# MSS_CTRL_MSS_CTRL_50D00000h register map
Vendor: Texas Instruments
Registers are 32-bit, read-write, reset values left out (the file's numbers can be read two ways) unless marked. A register's access mark holds for its fields unless they carry their own. Offsets are as the file gives them; [hi:lo] are bit positions.

## MSS_CTRL (part 5 of 6)
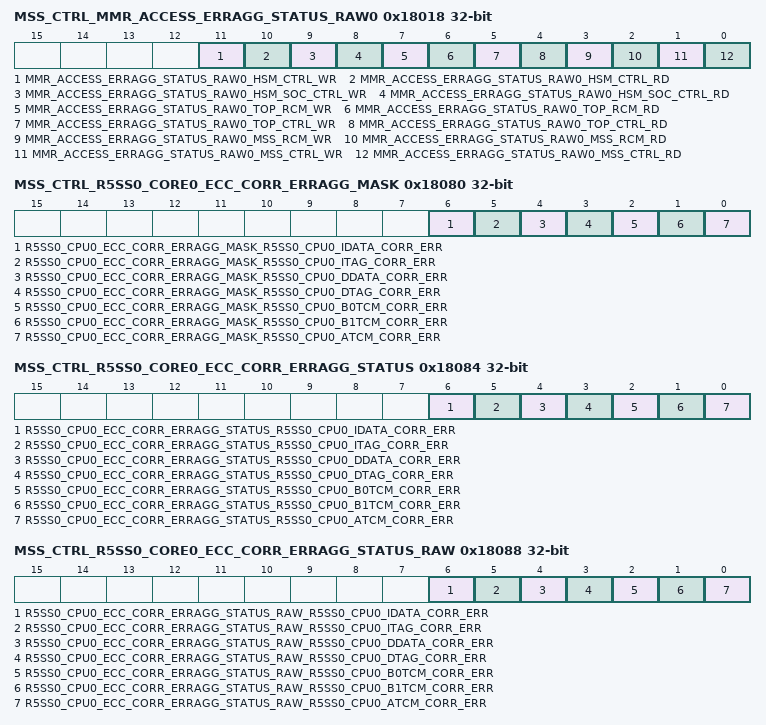
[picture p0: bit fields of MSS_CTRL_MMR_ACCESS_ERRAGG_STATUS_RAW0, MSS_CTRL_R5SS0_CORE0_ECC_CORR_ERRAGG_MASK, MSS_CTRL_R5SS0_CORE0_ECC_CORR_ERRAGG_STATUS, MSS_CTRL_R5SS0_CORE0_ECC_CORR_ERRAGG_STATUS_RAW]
0x18018 MSS_CTRL_MMR_ACCESS_ERRAGG_STATUS_RAW0
  [11] MMR_ACCESS_ERRAGG_STATUS_RAW0_HSM_CTRL_WR — Raw Status of Interrupt from HSM_CTRL. Set irrespective if the Interupt is masked or unmasked in MMR_ACCESS_ERRAGG_MASK0
  [10] MMR_ACCESS_ERRAGG_STATUS_RAW0_HSM_CTRL_RD — Raw Status of Interrupt from HSM_CTRL. Set irrespective if the Interupt is masked or unmasked in MMR_ACCESS_ERRAGG_MASK0
  [9] MMR_ACCESS_ERRAGG_STATUS_RAW0_HSM_SOC_CTRL_WR — Raw Status of Interrupt from HSM_SOC_CTRL. Set irrespective if the Interupt is masked or unmasked in MMR_ACCESS_ERRAGG_MASK0
  [8] MMR_ACCESS_ERRAGG_STATUS_RAW0_HSM_SOC_CTRL_RD — Raw Status of Interrupt from HSM_SOC_CTRL. Set irrespective if the Interupt is masked or unmasked in MMR_ACCESS_ERRAGG_MASK0
  [7] MMR_ACCESS_ERRAGG_STATUS_RAW0_TOP_RCM_WR — Raw Status of Interrupt from TOP_RCM. Set irrespective if the Interupt is masked or unmasked in MMR_ACCESS_ERRAGG_MASK0
  [6] MMR_ACCESS_ERRAGG_STATUS_RAW0_TOP_RCM_RD — Raw Status of Interrupt from TOP_RCM. Set irrespective if the Interupt is masked or unmasked in MMR_ACCESS_ERRAGG_MASK0
  [5] MMR_ACCESS_ERRAGG_STATUS_RAW0_TOP_CTRL_WR — Raw Status of Interrupt from TOP_CTRL. Set irrespective if the Interupt is masked or unmasked in MMR_ACCESS_ERRAGG_MASK0
  [4] MMR_ACCESS_ERRAGG_STATUS_RAW0_TOP_CTRL_RD — Raw Status of Interrupt from TOP_CTRL. Set irrespective if the Interupt is masked or unmasked in MMR_ACCESS_ERRAGG_MASK0
  [3] MMR_ACCESS_ERRAGG_STATUS_RAW0_MSS_RCM_WR — Raw Status of Interrupt from MSS_RCM. Set irrespective if the Interupt is masked or unmasked in MMR_ACCESS_ERRAGG_MASK0
  [2] MMR_ACCESS_ERRAGG_STATUS_RAW0_MSS_RCM_RD — Raw Status of Interrupt from MSS_RCM. Set irrespective if the Interupt is masked or unmasked in MMR_ACCESS_ERRAGG_MASK0
  [1] MMR_ACCESS_ERRAGG_STATUS_RAW0_MSS_CTRL_WR — Raw Status of Interrupt from MSS_CTRL. Set irrespective if the Interupt is masked or unmasked in MMR_ACCESS_ERRAGG_MASK0
  [0] MMR_ACCESS_ERRAGG_STATUS_RAW0_MSS_CTRL_RD — Raw Status of Interrupt from MSS_CTRL. Set irrespective if the Interupt is masked or unmasked in MMR_ACCESS_ERRAGG_MASK0
0x18080 MSS_CTRL_R5SS0_CORE0_ECC_CORR_ERRAGG_MASK
  [6] R5SS0_CPU0_ECC_CORR_ERRAGG_MASK_R5SS0_CPU0_IDATA_CORR_ERR — Mask Interrupt for correctable errors to aggregated Interrupt of corresponding CPU1'b1 : Interrupt is Masked1'b0 : Interrupt is Unmasked
  [5] R5SS0_CPU0_ECC_CORR_ERRAGG_MASK_R5SS0_CPU0_ITAG_CORR_ERR — Mask Interrupt for correctable errors to aggregated Interrupt of corresponding CPU1'b1 : Interrupt is Masked1'b0 : Interrupt is Unmasked
  [4] R5SS0_CPU0_ECC_CORR_ERRAGG_MASK_R5SS0_CPU0_DDATA_CORR_ERR — Mask Interrupt for correctable errors to aggregated Interrupt of corresponding CPU1'b1 : Interrupt is Masked1'b0 : Interrupt is Unmasked
  [3] R5SS0_CPU0_ECC_CORR_ERRAGG_MASK_R5SS0_CPU0_DTAG_CORR_ERR — Mask Interrupt for correctable errors to aggregated Interrupt of corresponding CPU1'b1 : Interrupt is Masked1'b0 : Interrupt is Unmasked
  [2] R5SS0_CPU0_ECC_CORR_ERRAGG_MASK_R5SS0_CPU0_B0TCM_CORR_ERR — Mask Interrupt for correctable errors to aggregated Interrupt of corresponding CPU1'b1 : Interrupt is Masked1'b0 : Interrupt is Unmasked
  [1] R5SS0_CPU0_ECC_CORR_ERRAGG_MASK_R5SS0_CPU0_B1TCM_CORR_ERR — Mask Interrupt for correctable errors to aggregated Interrupt of corresponding CPU1'b1 : Interrupt is Masked1'b0 : Interrupt is Unmasked
  [0] R5SS0_CPU0_ECC_CORR_ERRAGG_MASK_R5SS0_CPU0_ATCM_CORR_ERR — Mask Interrupt for correctable errors to aggregated Interrupt of corresponding CPU1'b1 : Interrupt is Masked1'b0 : Interrupt is Unmasked
0x18084 MSS_CTRL_R5SS0_CORE0_ECC_CORR_ERRAGG_STATUS
  [6] R5SS0_CPU0_ECC_CORR_ERRAGG_STATUS_R5SS0_CPU0_IDATA_CORR_ERR — Status of Interrupt from correctable error of corresponding CPUSet only if Interupt is unmasked in corresponding R5SS*_CPU*_ECC_CORR_ERRAGG_MASK registerWrie 0x1 to clear this interrupt.
  [5] R5SS0_CPU0_ECC_CORR_ERRAGG_STATUS_R5SS0_CPU0_ITAG_CORR_ERR — Status of Interrupt from correctable error of corresponding CPUSet only if Interupt is unmasked in corresponding R5SS*_CPU*_ECC_CORR_ERRAGG_MASK registerWrie 0x1 to clear this interrupt.
  [4] R5SS0_CPU0_ECC_CORR_ERRAGG_STATUS_R5SS0_CPU0_DDATA_CORR_ERR — Status of Interrupt from correctable error of corresponding CPUSet only if Interupt is unmasked in corresponding R5SS*_CPU*_ECC_CORR_ERRAGG_MASK registerWrie 0x1 to clear this interrupt.
  [3] R5SS0_CPU0_ECC_CORR_ERRAGG_STATUS_R5SS0_CPU0_DTAG_CORR_ERR — Status of Interrupt from correctable error of corresponding CPUSet only if Interupt is unmasked in corresponding R5SS*_CPU*_ECC_CORR_ERRAGG_MASK registerWrie 0x1 to clear this interrupt.
  [2] R5SS0_CPU0_ECC_CORR_ERRAGG_STATUS_R5SS0_CPU0_B0TCM_CORR_ERR — Status of Interrupt from correctable error of corresponding CPUSet only if Interupt is unmasked in corresponding R5SS*_CPU*_ECC_CORR_ERRAGG_MASK registerWrie 0x1 to clear this interrupt.
  [1] R5SS0_CPU0_ECC_CORR_ERRAGG_STATUS_R5SS0_CPU0_B1TCM_CORR_ERR — Status of Interrupt from correctable error of corresponding CPUSet only if Interupt is unmasked in corresponding R5SS*_CPU*_ECC_CORR_ERRAGG_MASK registerWrie 0x1 to clear this interrupt.
  [0] R5SS0_CPU0_ECC_CORR_ERRAGG_STATUS_R5SS0_CPU0_ATCM_CORR_ERR — Status of Interrupt from correctable error of corresponding CPUSet only if Interupt is unmasked in corresponding R5SS*_CPU*_ECC_CORR_ERRAGG_MASK registerWrie 0x1 to clear this interrupt.
0x18088 MSS_CTRL_R5SS0_CORE0_ECC_CORR_ERRAGG_STATUS_RAW
  [6] R5SS0_CPU0_ECC_CORR_ERRAGG_STATUS_RAW_R5SS0_CPU0_IDATA_CORR_ERR — Raw Status of Interrupt from correctable error of corresponding CPUSet only if Interupt is unmasked in corresponding R5SS*_CPU*_ECC_CORR_ERRAGG_MASK registerWrie 0x1 to clear this interrupt.
  [5] R5SS0_CPU0_ECC_CORR_ERRAGG_STATUS_RAW_R5SS0_CPU0_ITAG_CORR_ERR — Raw Status of Interrupt from correctable error of corresponding CPUSet only if Interupt is unmasked in corresponding R5SS*_CPU*_ECC_CORR_ERRAGG_MASK registerWrie 0x1 to clear this interrupt.
  [4] R5SS0_CPU0_ECC_CORR_ERRAGG_STATUS_RAW_R5SS0_CPU0_DDATA_CORR_ERR — Raw Status of Interrupt from correctable error of corresponding CPUSet only if Interupt is unmasked in corresponding R5SS*_CPU*_ECC_CORR_ERRAGG_MASK registerWrie 0x1 to clear this interrupt.
  [3] R5SS0_CPU0_ECC_CORR_ERRAGG_STATUS_RAW_R5SS0_CPU0_DTAG_CORR_ERR — Raw Status of Interrupt from correctable error of corresponding CPUSet only if Interupt is unmasked in corresponding R5SS*_CPU*_ECC_CORR_ERRAGG_MASK registerWrie 0x1 to clear this interrupt.
  [2] R5SS0_CPU0_ECC_CORR_ERRAGG_STATUS_RAW_R5SS0_CPU0_B0TCM_CORR_ERR — Raw Status of Interrupt from correctable error of corresponding CPUSet only if Interupt is unmasked in corresponding R5SS*_CPU*_ECC_CORR_ERRAGG_MASK registerWrie 0x1 to clear this interrupt.
  [1] R5SS0_CPU0_ECC_CORR_ERRAGG_STATUS_RAW_R5SS0_CPU0_B1TCM_CORR_ERR — Raw Status of Interrupt from correctable error of corresponding CPUSet only if Interupt is unmasked in corresponding R5SS*_CPU*_ECC_CORR_ERRAGG_MASK registerWrie 0x1 to clear this interrupt.
  [0] R5SS0_CPU0_ECC_CORR_ERRAGG_STATUS_RAW_R5SS0_CPU0_ATCM_CORR_ERR — Raw Status of Interrupt from correctable error of corresponding CPUSet only if Interupt is unmasked in corresponding R5SS*_CPU*_ECC_CORR_ERRAGG_MASK registerWrie 0x1 to clear this interrupt.
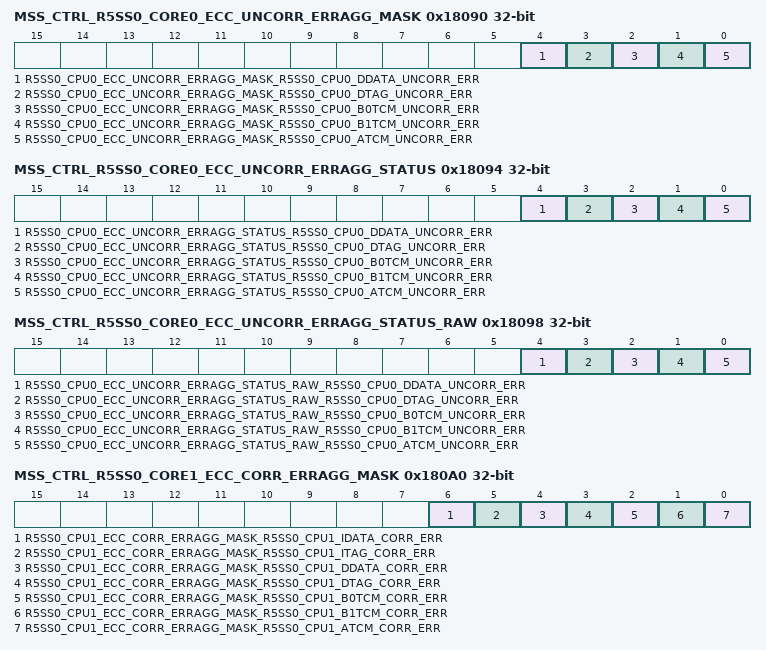
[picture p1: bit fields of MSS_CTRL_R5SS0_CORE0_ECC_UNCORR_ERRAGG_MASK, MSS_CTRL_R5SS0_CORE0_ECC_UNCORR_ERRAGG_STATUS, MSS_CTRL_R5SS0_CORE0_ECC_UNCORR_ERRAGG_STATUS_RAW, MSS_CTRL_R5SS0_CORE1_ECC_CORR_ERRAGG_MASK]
0x18090 MSS_CTRL_R5SS0_CORE0_ECC_UNCORR_ERRAGG_MASK
  [4] R5SS0_CPU0_ECC_UNCORR_ERRAGG_MASK_R5SS0_CPU0_DDATA_UNCORR_ERR — Mask Interrupt for correctable errors to aggregated Interrupt of corresponding CPU1'b1 : Interrupt is Masked1'b0 : Interrupt is Unmasked
  [3] R5SS0_CPU0_ECC_UNCORR_ERRAGG_MASK_R5SS0_CPU0_DTAG_UNCORR_ERR — Mask Interrupt for correctable errors to aggregated Interrupt of corresponding CPU1'b1 : Interrupt is Masked1'b0 : Interrupt is Unmasked
  [2] R5SS0_CPU0_ECC_UNCORR_ERRAGG_MASK_R5SS0_CPU0_B0TCM_UNCORR_ERR — Mask Interrupt for correctable errors to aggregated Interrupt of corresponding CPU1'b1 : Interrupt is Masked1'b0 : Interrupt is Unmasked
  [1] R5SS0_CPU0_ECC_UNCORR_ERRAGG_MASK_R5SS0_CPU0_B1TCM_UNCORR_ERR — Mask Interrupt for correctable errors to aggregated Interrupt of corresponding CPU1'b1 : Interrupt is Masked1'b0 : Interrupt is Unmasked
  [0] R5SS0_CPU0_ECC_UNCORR_ERRAGG_MASK_R5SS0_CPU0_ATCM_UNCORR_ERR — Mask Interrupt for correctable errors to aggregated Interrupt of corresponding CPU1'b1 : Interrupt is Masked1'b0 : Interrupt is Unmasked
0x18094 MSS_CTRL_R5SS0_CORE0_ECC_UNCORR_ERRAGG_STATUS
  [4] R5SS0_CPU0_ECC_UNCORR_ERRAGG_STATUS_R5SS0_CPU0_DDATA_UNCORR_ERR — Status of Interrupt from correctable error of corresponding CPUSet only if Interupt is unmasked in corresponding R5SS*_CPU*_ECC_UNCORR_ERRAGG_MASK registerWrie 0x1 to clear this interrupt.
  [3] R5SS0_CPU0_ECC_UNCORR_ERRAGG_STATUS_R5SS0_CPU0_DTAG_UNCORR_ERR — Status of Interrupt from correctable error of corresponding CPUSet only if Interupt is unmasked in corresponding R5SS*_CPU*_ECC_UNCORR_ERRAGG_MASK registerWrie 0x1 to clear this interrupt.
  [2] R5SS0_CPU0_ECC_UNCORR_ERRAGG_STATUS_R5SS0_CPU0_B0TCM_UNCORR_ERR — Status of Interrupt from correctable error of corresponding CPUSet only if Interupt is unmasked in corresponding R5SS*_CPU*_ECC_UNCORR_ERRAGG_MASK registerWrie 0x1 to clear this interrupt.
  [1] R5SS0_CPU0_ECC_UNCORR_ERRAGG_STATUS_R5SS0_CPU0_B1TCM_UNCORR_ERR — Status of Interrupt from correctable error of corresponding CPUSet only if Interupt is unmasked in corresponding R5SS*_CPU*_ECC_UNCORR_ERRAGG_MASK registerWrie 0x1 to clear this interrupt.
  [0] R5SS0_CPU0_ECC_UNCORR_ERRAGG_STATUS_R5SS0_CPU0_ATCM_UNCORR_ERR — Status of Interrupt from correctable error of corresponding CPUSet only if Interupt is unmasked in corresponding R5SS*_CPU*_ECC_UNCORR_ERRAGG_MASK registerWrie 0x1 to clear this interrupt.
0x18098 MSS_CTRL_R5SS0_CORE0_ECC_UNCORR_ERRAGG_STATUS_RAW
  [4] R5SS0_CPU0_ECC_UNCORR_ERRAGG_STATUS_RAW_R5SS0_CPU0_DDATA_UNCORR_ERR — Raw Status of Interrupt from correctable error of corresponding CPUSet only if Interupt is unmasked in corresponding R5SS*_CPU*_ECC_UNCORR_ERRAGG_MASK registerWrie 0x1 to clear this interrupt.
  [3] R5SS0_CPU0_ECC_UNCORR_ERRAGG_STATUS_RAW_R5SS0_CPU0_DTAG_UNCORR_ERR — Raw Status of Interrupt from correctable error of corresponding CPUSet only if Interupt is unmasked in corresponding R5SS*_CPU*_ECC_UNCORR_ERRAGG_MASK registerWrie 0x1 to clear this interrupt.
  [2] R5SS0_CPU0_ECC_UNCORR_ERRAGG_STATUS_RAW_R5SS0_CPU0_B0TCM_UNCORR_ERR — Raw Status of Interrupt from correctable error of corresponding CPUSet only if Interupt is unmasked in corresponding R5SS*_CPU*_ECC_UNCORR_ERRAGG_MASK registerWrie 0x1 to clear this interrupt.
  [1] R5SS0_CPU0_ECC_UNCORR_ERRAGG_STATUS_RAW_R5SS0_CPU0_B1TCM_UNCORR_ERR — Raw Status of Interrupt from correctable error of corresponding CPUSet only if Interupt is unmasked in corresponding R5SS*_CPU*_ECC_UNCORR_ERRAGG_MASK registerWrie 0x1 to clear this interrupt.
  [0] R5SS0_CPU0_ECC_UNCORR_ERRAGG_STATUS_RAW_R5SS0_CPU0_ATCM_UNCORR_ERR — Raw Status of Interrupt from correctable error of corresponding CPUSet only if Interupt is unmasked in corresponding R5SS*_CPU*_ECC_UNCORR_ERRAGG_MASK registerWrie 0x1 to clear this interrupt.
0x180A0 MSS_CTRL_R5SS0_CORE1_ECC_CORR_ERRAGG_MASK
  [6] R5SS0_CPU1_ECC_CORR_ERRAGG_MASK_R5SS0_CPU1_IDATA_CORR_ERR — Mask Interrupt for correctable errors to aggregated Interrupt of corresponding CPU1'b1 : Interrupt is Masked1'b0 : Interrupt is Unmasked
  [5] R5SS0_CPU1_ECC_CORR_ERRAGG_MASK_R5SS0_CPU1_ITAG_CORR_ERR — Mask Interrupt for correctable errors to aggregated Interrupt of corresponding CPU1'b1 : Interrupt is Masked1'b0 : Interrupt is Unmasked
  [4] R5SS0_CPU1_ECC_CORR_ERRAGG_MASK_R5SS0_CPU1_DDATA_CORR_ERR — Mask Interrupt for correctable errors to aggregated Interrupt of corresponding CPU1'b1 : Interrupt is Masked1'b0 : Interrupt is Unmasked
  [3] R5SS0_CPU1_ECC_CORR_ERRAGG_MASK_R5SS0_CPU1_DTAG_CORR_ERR — Mask Interrupt for correctable errors to aggregated Interrupt of corresponding CPU1'b1 : Interrupt is Masked1'b0 : Interrupt is Unmasked
  [2] R5SS0_CPU1_ECC_CORR_ERRAGG_MASK_R5SS0_CPU1_B0TCM_CORR_ERR — Mask Interrupt for correctable errors to aggregated Interrupt of corresponding CPU1'b1 : Interrupt is Masked1'b0 : Interrupt is Unmasked
  [1] R5SS0_CPU1_ECC_CORR_ERRAGG_MASK_R5SS0_CPU1_B1TCM_CORR_ERR — Mask Interrupt for correctable errors to aggregated Interrupt of corresponding CPU1'b1 : Interrupt is Masked1'b0 : Interrupt is Unmasked
  [0] R5SS0_CPU1_ECC_CORR_ERRAGG_MASK_R5SS0_CPU1_ATCM_CORR_ERR — Mask Interrupt for correctable errors to aggregated Interrupt of corresponding CPU1'b1 : Interrupt is Masked1'b0 : Interrupt is Unmasked
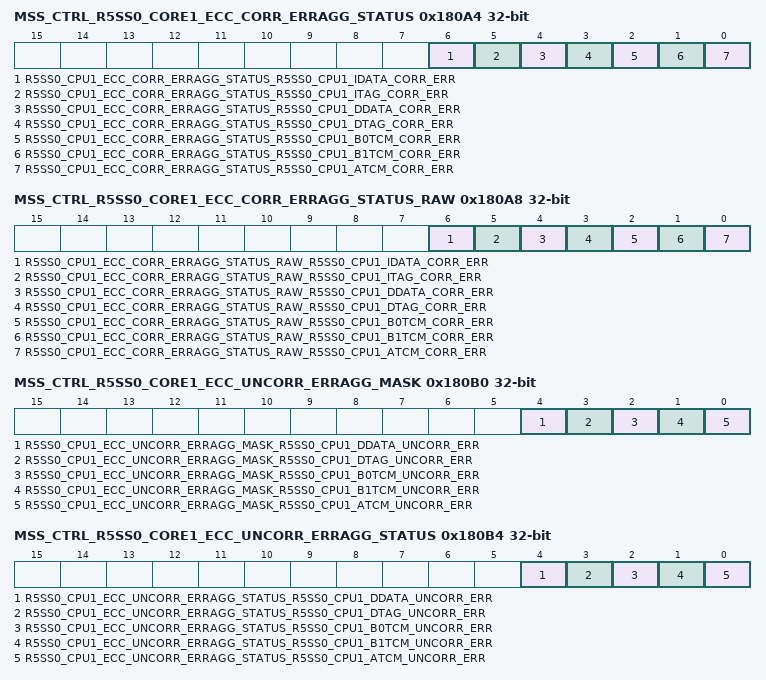
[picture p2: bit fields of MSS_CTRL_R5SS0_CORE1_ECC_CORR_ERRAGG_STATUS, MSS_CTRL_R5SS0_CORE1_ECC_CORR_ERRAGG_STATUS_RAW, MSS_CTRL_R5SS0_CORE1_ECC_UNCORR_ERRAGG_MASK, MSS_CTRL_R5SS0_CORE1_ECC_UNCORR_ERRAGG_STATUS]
0x180A4 MSS_CTRL_R5SS0_CORE1_ECC_CORR_ERRAGG_STATUS
  [6] R5SS0_CPU1_ECC_CORR_ERRAGG_STATUS_R5SS0_CPU1_IDATA_CORR_ERR — Status of Interrupt from correctable error of corresponding CPUSet only if Interupt is unmasked in corresponding R5SS*_CPU*_ECC_CORR_ERRAGG_MASK registerWrie 0x1 to clear this interrupt.
  [5] R5SS0_CPU1_ECC_CORR_ERRAGG_STATUS_R5SS0_CPU1_ITAG_CORR_ERR — Status of Interrupt from correctable error of corresponding CPUSet only if Interupt is unmasked in corresponding R5SS*_CPU*_ECC_CORR_ERRAGG_MASK registerWrie 0x1 to clear this interrupt.
  [4] R5SS0_CPU1_ECC_CORR_ERRAGG_STATUS_R5SS0_CPU1_DDATA_CORR_ERR — Status of Interrupt from correctable error of corresponding CPUSet only if Interupt is unmasked in corresponding R5SS*_CPU*_ECC_CORR_ERRAGG_MASK registerWrie 0x1 to clear this interrupt.
  [3] R5SS0_CPU1_ECC_CORR_ERRAGG_STATUS_R5SS0_CPU1_DTAG_CORR_ERR — Status of Interrupt from correctable error of corresponding CPUSet only if Interupt is unmasked in corresponding R5SS*_CPU*_ECC_CORR_ERRAGG_MASK registerWrie 0x1 to clear this interrupt.
  [2] R5SS0_CPU1_ECC_CORR_ERRAGG_STATUS_R5SS0_CPU1_B0TCM_CORR_ERR — Status of Interrupt from correctable error of corresponding CPUSet only if Interupt is unmasked in corresponding R5SS*_CPU*_ECC_CORR_ERRAGG_MASK registerWrie 0x1 to clear this interrupt.
  [1] R5SS0_CPU1_ECC_CORR_ERRAGG_STATUS_R5SS0_CPU1_B1TCM_CORR_ERR — Status of Interrupt from correctable error of corresponding CPUSet only if Interupt is unmasked in corresponding R5SS*_CPU*_ECC_CORR_ERRAGG_MASK registerWrie 0x1 to clear this interrupt.
  [0] R5SS0_CPU1_ECC_CORR_ERRAGG_STATUS_R5SS0_CPU1_ATCM_CORR_ERR — Status of Interrupt from correctable error of corresponding CPUSet only if Interupt is unmasked in corresponding R5SS*_CPU*_ECC_CORR_ERRAGG_MASK registerWrie 0x1 to clear this interrupt.
0x180A8 MSS_CTRL_R5SS0_CORE1_ECC_CORR_ERRAGG_STATUS_RAW
  [6] R5SS0_CPU1_ECC_CORR_ERRAGG_STATUS_RAW_R5SS0_CPU1_IDATA_CORR_ERR — Raw Status of Interrupt from correctable error of corresponding CPUSet only if Interupt is unmasked in corresponding R5SS*_CPU*_ECC_CORR_ERRAGG_MASK registerWrie 0x1 to clear this interrupt.
  [5] R5SS0_CPU1_ECC_CORR_ERRAGG_STATUS_RAW_R5SS0_CPU1_ITAG_CORR_ERR — Raw Status of Interrupt from correctable error of corresponding CPUSet only if Interupt is unmasked in corresponding R5SS*_CPU*_ECC_CORR_ERRAGG_MASK registerWrie 0x1 to clear this interrupt.
  [4] R5SS0_CPU1_ECC_CORR_ERRAGG_STATUS_RAW_R5SS0_CPU1_DDATA_CORR_ERR — Raw Status of Interrupt from correctable error of corresponding CPUSet only if Interupt is unmasked in corresponding R5SS*_CPU*_ECC_CORR_ERRAGG_MASK registerWrie 0x1 to clear this interrupt.
  [3] R5SS0_CPU1_ECC_CORR_ERRAGG_STATUS_RAW_R5SS0_CPU1_DTAG_CORR_ERR — Raw Status of Interrupt from correctable error of corresponding CPUSet only if Interupt is unmasked in corresponding R5SS*_CPU*_ECC_CORR_ERRAGG_MASK registerWrie 0x1 to clear this interrupt.
  [2] R5SS0_CPU1_ECC_CORR_ERRAGG_STATUS_RAW_R5SS0_CPU1_B0TCM_CORR_ERR — Raw Status of Interrupt from correctable error of corresponding CPUSet only if Interupt is unmasked in corresponding R5SS*_CPU*_ECC_CORR_ERRAGG_MASK registerWrie 0x1 to clear this interrupt.
  [1] R5SS0_CPU1_ECC_CORR_ERRAGG_STATUS_RAW_R5SS0_CPU1_B1TCM_CORR_ERR — Raw Status of Interrupt from correctable error of corresponding CPUSet only if Interupt is unmasked in corresponding R5SS*_CPU*_ECC_CORR_ERRAGG_MASK registerWrie 0x1 to clear this interrupt.
  [0] R5SS0_CPU1_ECC_CORR_ERRAGG_STATUS_RAW_R5SS0_CPU1_ATCM_CORR_ERR — Raw Status of Interrupt from correctable error of corresponding CPUSet only if Interupt is unmasked in corresponding R5SS*_CPU*_ECC_CORR_ERRAGG_MASK registerWrie 0x1 to clear this interrupt.
0x180B0 MSS_CTRL_R5SS0_CORE1_ECC_UNCORR_ERRAGG_MASK
  [4] R5SS0_CPU1_ECC_UNCORR_ERRAGG_MASK_R5SS0_CPU1_DDATA_UNCORR_ERR — Mask Interrupt for correctable errors to aggregated Interrupt of corresponding CPU1'b1 : Interrupt is Masked1'b0 : Interrupt is Unmasked
  [3] R5SS0_CPU1_ECC_UNCORR_ERRAGG_MASK_R5SS0_CPU1_DTAG_UNCORR_ERR — Mask Interrupt for correctable errors to aggregated Interrupt of corresponding CPU1'b1 : Interrupt is Masked1'b0 : Interrupt is Unmasked
  [2] R5SS0_CPU1_ECC_UNCORR_ERRAGG_MASK_R5SS0_CPU1_B0TCM_UNCORR_ERR — Mask Interrupt for correctable errors to aggregated Interrupt of corresponding CPU1'b1 : Interrupt is Masked1'b0 : Interrupt is Unmasked
  [1] R5SS0_CPU1_ECC_UNCORR_ERRAGG_MASK_R5SS0_CPU1_B1TCM_UNCORR_ERR — Mask Interrupt for correctable errors to aggregated Interrupt of corresponding CPU1'b1 : Interrupt is Masked1'b0 : Interrupt is Unmasked
  [0] R5SS0_CPU1_ECC_UNCORR_ERRAGG_MASK_R5SS0_CPU1_ATCM_UNCORR_ERR — Mask Interrupt for correctable errors to aggregated Interrupt of corresponding CPU1'b1 : Interrupt is Masked1'b0 : Interrupt is Unmasked
0x180B4 MSS_CTRL_R5SS0_CORE1_ECC_UNCORR_ERRAGG_STATUS
  [4] R5SS0_CPU1_ECC_UNCORR_ERRAGG_STATUS_R5SS0_CPU1_DDATA_UNCORR_ERR — Status of Interrupt from correctable error of corresponding CPUSet only if Interupt is unmasked in corresponding R5SS*_CPU*_ECC_UNCORR_ERRAGG_MASK registerWrie 0x1 to clear this interrupt.
  [3] R5SS0_CPU1_ECC_UNCORR_ERRAGG_STATUS_R5SS0_CPU1_DTAG_UNCORR_ERR — Status of Interrupt from correctable error of corresponding CPUSet only if Interupt is unmasked in corresponding R5SS*_CPU*_ECC_UNCORR_ERRAGG_MASK registerWrie 0x1 to clear this interrupt.
  [2] R5SS0_CPU1_ECC_UNCORR_ERRAGG_STATUS_R5SS0_CPU1_B0TCM_UNCORR_ERR — Status of Interrupt from correctable error of corresponding CPUSet only if Interupt is unmasked in corresponding R5SS*_CPU*_ECC_UNCORR_ERRAGG_MASK registerWrie 0x1 to clear this interrupt.
  [1] R5SS0_CPU1_ECC_UNCORR_ERRAGG_STATUS_R5SS0_CPU1_B1TCM_UNCORR_ERR — Status of Interrupt from correctable error of corresponding CPUSet only if Interupt is unmasked in corresponding R5SS*_CPU*_ECC_UNCORR_ERRAGG_MASK registerWrie 0x1 to clear this interrupt.
  [0] R5SS0_CPU1_ECC_UNCORR_ERRAGG_STATUS_R5SS0_CPU1_ATCM_UNCORR_ERR — Status of Interrupt from correctable error of corresponding CPUSet only if Interupt is unmasked in corresponding R5SS*_CPU*_ECC_UNCORR_ERRAGG_MASK registerWrie 0x1 to clear this interrupt.
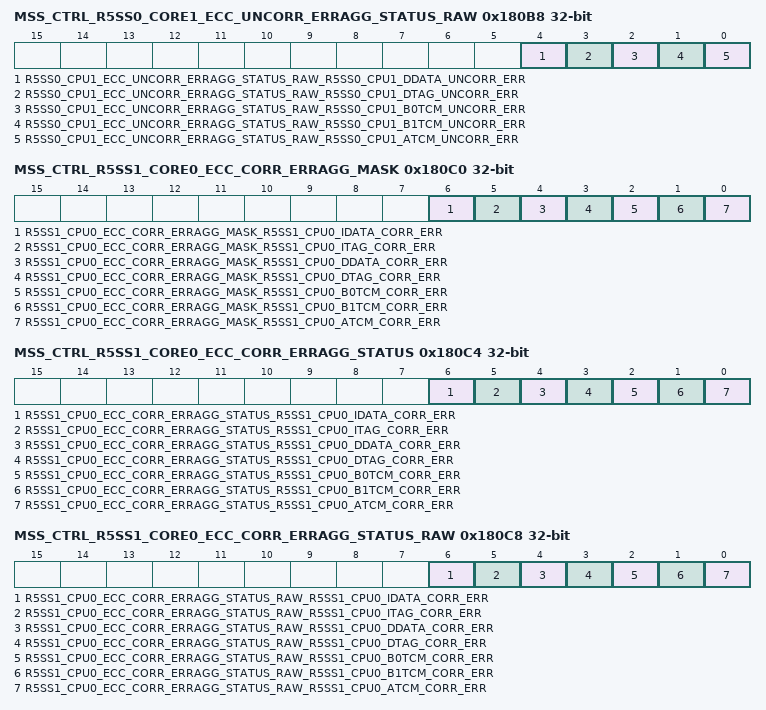
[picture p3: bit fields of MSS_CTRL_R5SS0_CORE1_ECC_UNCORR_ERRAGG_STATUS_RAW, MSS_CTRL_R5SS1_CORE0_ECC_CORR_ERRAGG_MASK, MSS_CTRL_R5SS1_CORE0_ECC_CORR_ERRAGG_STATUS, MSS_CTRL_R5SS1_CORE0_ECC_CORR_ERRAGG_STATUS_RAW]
0x180B8 MSS_CTRL_R5SS0_CORE1_ECC_UNCORR_ERRAGG_STATUS_RAW
  [4] R5SS0_CPU1_ECC_UNCORR_ERRAGG_STATUS_RAW_R5SS0_CPU1_DDATA_UNCORR_ERR — Raw Status of Interrupt from correctable error of corresponding CPUSet only if Interupt is unmasked in corresponding R5SS*_CPU*_ECC_UNCORR_ERRAGG_MASK registerWrie 0x1 to clear this interrupt.
  [3] R5SS0_CPU1_ECC_UNCORR_ERRAGG_STATUS_RAW_R5SS0_CPU1_DTAG_UNCORR_ERR — Raw Status of Interrupt from correctable error of corresponding CPUSet only if Interupt is unmasked in corresponding R5SS*_CPU*_ECC_UNCORR_ERRAGG_MASK registerWrie 0x1 to clear this interrupt.
  [2] R5SS0_CPU1_ECC_UNCORR_ERRAGG_STATUS_RAW_R5SS0_CPU1_B0TCM_UNCORR_ERR — Raw Status of Interrupt from correctable error of corresponding CPUSet only if Interupt is unmasked in corresponding R5SS*_CPU*_ECC_UNCORR_ERRAGG_MASK registerWrie 0x1 to clear this interrupt.
  [1] R5SS0_CPU1_ECC_UNCORR_ERRAGG_STATUS_RAW_R5SS0_CPU1_B1TCM_UNCORR_ERR — Raw Status of Interrupt from correctable error of corresponding CPUSet only if Interupt is unmasked in corresponding R5SS*_CPU*_ECC_UNCORR_ERRAGG_MASK registerWrie 0x1 to clear this interrupt.
  [0] R5SS0_CPU1_ECC_UNCORR_ERRAGG_STATUS_RAW_R5SS0_CPU1_ATCM_UNCORR_ERR — Raw Status of Interrupt from correctable error of corresponding CPUSet only if Interupt is unmasked in corresponding R5SS*_CPU*_ECC_UNCORR_ERRAGG_MASK registerWrie 0x1 to clear this interrupt.
0x180C0 MSS_CTRL_R5SS1_CORE0_ECC_CORR_ERRAGG_MASK
  [6] R5SS1_CPU0_ECC_CORR_ERRAGG_MASK_R5SS1_CPU0_IDATA_CORR_ERR — Mask Interrupt for correctable errors to aggregated Interrupt of corresponding CPU1'b1 : Interrupt is Masked1'b0 : Interrupt is Unmasked
  [5] R5SS1_CPU0_ECC_CORR_ERRAGG_MASK_R5SS1_CPU0_ITAG_CORR_ERR — Mask Interrupt for correctable errors to aggregated Interrupt of corresponding CPU1'b1 : Interrupt is Masked1'b0 : Interrupt is Unmasked
  [4] R5SS1_CPU0_ECC_CORR_ERRAGG_MASK_R5SS1_CPU0_DDATA_CORR_ERR — Mask Interrupt for correctable errors to aggregated Interrupt of corresponding CPU1'b1 : Interrupt is Masked1'b0 : Interrupt is Unmasked
  [3] R5SS1_CPU0_ECC_CORR_ERRAGG_MASK_R5SS1_CPU0_DTAG_CORR_ERR — Mask Interrupt for correctable errors to aggregated Interrupt of corresponding CPU1'b1 : Interrupt is Masked1'b0 : Interrupt is Unmasked
  [2] R5SS1_CPU0_ECC_CORR_ERRAGG_MASK_R5SS1_CPU0_B0TCM_CORR_ERR — Mask Interrupt for correctable errors to aggregated Interrupt of corresponding CPU1'b1 : Interrupt is Masked1'b0 : Interrupt is Unmasked
  [1] R5SS1_CPU0_ECC_CORR_ERRAGG_MASK_R5SS1_CPU0_B1TCM_CORR_ERR — Mask Interrupt for correctable errors to aggregated Interrupt of corresponding CPU1'b1 : Interrupt is Masked1'b0 : Interrupt is Unmasked
  [0] R5SS1_CPU0_ECC_CORR_ERRAGG_MASK_R5SS1_CPU0_ATCM_CORR_ERR — Mask Interrupt for correctable errors to aggregated Interrupt of corresponding CPU1'b1 : Interrupt is Masked1'b0 : Interrupt is Unmasked
0x180C4 MSS_CTRL_R5SS1_CORE0_ECC_CORR_ERRAGG_STATUS
  [6] R5SS1_CPU0_ECC_CORR_ERRAGG_STATUS_R5SS1_CPU0_IDATA_CORR_ERR — Status of Interrupt from correctable error of corresponding CPUSet only if Interupt is unmasked in corresponding R5SS*_CPU*_ECC_CORR_ERRAGG_MASK registerWrie 0x1 to clear this interrupt.
  [5] R5SS1_CPU0_ECC_CORR_ERRAGG_STATUS_R5SS1_CPU0_ITAG_CORR_ERR — Status of Interrupt from correctable error of corresponding CPUSet only if Interupt is unmasked in corresponding R5SS*_CPU*_ECC_CORR_ERRAGG_MASK registerWrie 0x1 to clear this interrupt.
  [4] R5SS1_CPU0_ECC_CORR_ERRAGG_STATUS_R5SS1_CPU0_DDATA_CORR_ERR — Status of Interrupt from correctable error of corresponding CPUSet only if Interupt is unmasked in corresponding R5SS*_CPU*_ECC_CORR_ERRAGG_MASK registerWrie 0x1 to clear this interrupt.
  [3] R5SS1_CPU0_ECC_CORR_ERRAGG_STATUS_R5SS1_CPU0_DTAG_CORR_ERR — Status of Interrupt from correctable error of corresponding CPUSet only if Interupt is unmasked in corresponding R5SS*_CPU*_ECC_CORR_ERRAGG_MASK registerWrie 0x1 to clear this interrupt.
  [2] R5SS1_CPU0_ECC_CORR_ERRAGG_STATUS_R5SS1_CPU0_B0TCM_CORR_ERR — Status of Interrupt from correctable error of corresponding CPUSet only if Interupt is unmasked in corresponding R5SS*_CPU*_ECC_CORR_ERRAGG_MASK registerWrie 0x1 to clear this interrupt.
  [1] R5SS1_CPU0_ECC_CORR_ERRAGG_STATUS_R5SS1_CPU0_B1TCM_CORR_ERR — Status of Interrupt from correctable error of corresponding CPUSet only if Interupt is unmasked in corresponding R5SS*_CPU*_ECC_CORR_ERRAGG_MASK registerWrie 0x1 to clear this interrupt.
  [0] R5SS1_CPU0_ECC_CORR_ERRAGG_STATUS_R5SS1_CPU0_ATCM_CORR_ERR — Status of Interrupt from correctable error of corresponding CPUSet only if Interupt is unmasked in corresponding R5SS*_CPU*_ECC_CORR_ERRAGG_MASK registerWrie 0x1 to clear this interrupt.
0x180C8 MSS_CTRL_R5SS1_CORE0_ECC_CORR_ERRAGG_STATUS_RAW
  [6] R5SS1_CPU0_ECC_CORR_ERRAGG_STATUS_RAW_R5SS1_CPU0_IDATA_CORR_ERR — Raw Status of Interrupt from correctable error of corresponding CPUSet only if Interupt is unmasked in corresponding R5SS*_CPU*_ECC_CORR_ERRAGG_MASK registerWrie 0x1 to clear this interrupt.
  [5] R5SS1_CPU0_ECC_CORR_ERRAGG_STATUS_RAW_R5SS1_CPU0_ITAG_CORR_ERR — Raw Status of Interrupt from correctable error of corresponding CPUSet only if Interupt is unmasked in corresponding R5SS*_CPU*_ECC_CORR_ERRAGG_MASK registerWrie 0x1 to clear this interrupt.
  [4] R5SS1_CPU0_ECC_CORR_ERRAGG_STATUS_RAW_R5SS1_CPU0_DDATA_CORR_ERR — Raw Status of Interrupt from correctable error of corresponding CPUSet only if Interupt is unmasked in corresponding R5SS*_CPU*_ECC_CORR_ERRAGG_MASK registerWrie 0x1 to clear this interrupt.
  [3] R5SS1_CPU0_ECC_CORR_ERRAGG_STATUS_RAW_R5SS1_CPU0_DTAG_CORR_ERR — Raw Status of Interrupt from correctable error of corresponding CPUSet only if Interupt is unmasked in corresponding R5SS*_CPU*_ECC_CORR_ERRAGG_MASK registerWrie 0x1 to clear this interrupt.
  [2] R5SS1_CPU0_ECC_CORR_ERRAGG_STATUS_RAW_R5SS1_CPU0_B0TCM_CORR_ERR — Raw Status of Interrupt from correctable error of corresponding CPUSet only if Interupt is unmasked in corresponding R5SS*_CPU*_ECC_CORR_ERRAGG_MASK registerWrie 0x1 to clear this interrupt.
  [1] R5SS1_CPU0_ECC_CORR_ERRAGG_STATUS_RAW_R5SS1_CPU0_B1TCM_CORR_ERR — Raw Status of Interrupt from correctable error of corresponding CPUSet only if Interupt is unmasked in corresponding R5SS*_CPU*_ECC_CORR_ERRAGG_MASK registerWrie 0x1 to clear this interrupt.
  [0] R5SS1_CPU0_ECC_CORR_ERRAGG_STATUS_RAW_R5SS1_CPU0_ATCM_CORR_ERR — Raw Status of Interrupt from correctable error of corresponding CPUSet only if Interupt is unmasked in corresponding R5SS*_CPU*_ECC_CORR_ERRAGG_MASK registerWrie 0x1 to clear this interrupt.
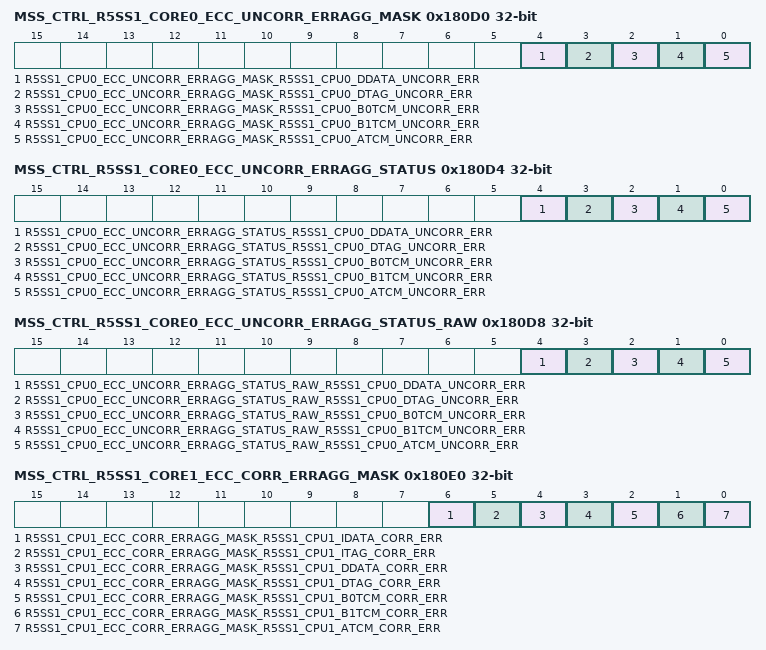
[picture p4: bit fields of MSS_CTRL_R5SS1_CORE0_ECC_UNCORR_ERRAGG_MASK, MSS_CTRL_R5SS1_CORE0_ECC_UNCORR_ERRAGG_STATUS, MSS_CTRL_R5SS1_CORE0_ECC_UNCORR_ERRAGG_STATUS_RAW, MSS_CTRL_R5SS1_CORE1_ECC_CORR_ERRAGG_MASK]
0x180D0 MSS_CTRL_R5SS1_CORE0_ECC_UNCORR_ERRAGG_MASK
  [4] R5SS1_CPU0_ECC_UNCORR_ERRAGG_MASK_R5SS1_CPU0_DDATA_UNCORR_ERR — Mask Interrupt for correctable errors to aggregated Interrupt of corresponding CPU1'b1 : Interrupt is Masked1'b0 : Interrupt is Unmasked
  [3] R5SS1_CPU0_ECC_UNCORR_ERRAGG_MASK_R5SS1_CPU0_DTAG_UNCORR_ERR — Mask Interrupt for correctable errors to aggregated Interrupt of corresponding CPU1'b1 : Interrupt is Masked1'b0 : Interrupt is Unmasked
  [2] R5SS1_CPU0_ECC_UNCORR_ERRAGG_MASK_R5SS1_CPU0_B0TCM_UNCORR_ERR — Mask Interrupt for correctable errors to aggregated Interrupt of corresponding CPU1'b1 : Interrupt is Masked1'b0 : Interrupt is Unmasked
  [1] R5SS1_CPU0_ECC_UNCORR_ERRAGG_MASK_R5SS1_CPU0_B1TCM_UNCORR_ERR — Mask Interrupt for correctable errors to aggregated Interrupt of corresponding CPU1'b1 : Interrupt is Masked1'b0 : Interrupt is Unmasked
  [0] R5SS1_CPU0_ECC_UNCORR_ERRAGG_MASK_R5SS1_CPU0_ATCM_UNCORR_ERR — Mask Interrupt for correctable errors to aggregated Interrupt of corresponding CPU1'b1 : Interrupt is Masked1'b0 : Interrupt is Unmasked
0x180D4 MSS_CTRL_R5SS1_CORE0_ECC_UNCORR_ERRAGG_STATUS
  [4] R5SS1_CPU0_ECC_UNCORR_ERRAGG_STATUS_R5SS1_CPU0_DDATA_UNCORR_ERR — Status of Interrupt from correctable error of corresponding CPUSet only if Interupt is unmasked in corresponding R5SS*_CPU*_ECC_UNCORR_ERRAGG_MASK registerWrie 0x1 to clear this interrupt.
  [3] R5SS1_CPU0_ECC_UNCORR_ERRAGG_STATUS_R5SS1_CPU0_DTAG_UNCORR_ERR — Status of Interrupt from correctable error of corresponding CPUSet only if Interupt is unmasked in corresponding R5SS*_CPU*_ECC_UNCORR_ERRAGG_MASK registerWrie 0x1 to clear this interrupt.
  [2] R5SS1_CPU0_ECC_UNCORR_ERRAGG_STATUS_R5SS1_CPU0_B0TCM_UNCORR_ERR — Status of Interrupt from correctable error of corresponding CPUSet only if Interupt is unmasked in corresponding R5SS*_CPU*_ECC_UNCORR_ERRAGG_MASK registerWrie 0x1 to clear this interrupt.
  [1] R5SS1_CPU0_ECC_UNCORR_ERRAGG_STATUS_R5SS1_CPU0_B1TCM_UNCORR_ERR — Status of Interrupt from correctable error of corresponding CPUSet only if Interupt is unmasked in corresponding R5SS*_CPU*_ECC_UNCORR_ERRAGG_MASK registerWrie 0x1 to clear this interrupt.
  [0] R5SS1_CPU0_ECC_UNCORR_ERRAGG_STATUS_R5SS1_CPU0_ATCM_UNCORR_ERR — Status of Interrupt from correctable error of corresponding CPUSet only if Interupt is unmasked in corresponding R5SS*_CPU*_ECC_UNCORR_ERRAGG_MASK registerWrie 0x1 to clear this interrupt.
0x180D8 MSS_CTRL_R5SS1_CORE0_ECC_UNCORR_ERRAGG_STATUS_RAW
  [4] R5SS1_CPU0_ECC_UNCORR_ERRAGG_STATUS_RAW_R5SS1_CPU0_DDATA_UNCORR_ERR — Raw Status of Interrupt from correctable error of corresponding CPUSet only if Interupt is unmasked in corresponding R5SS*_CPU*_ECC_UNCORR_ERRAGG_MASK registerWrie 0x1 to clear this interrupt.
  [3] R5SS1_CPU0_ECC_UNCORR_ERRAGG_STATUS_RAW_R5SS1_CPU0_DTAG_UNCORR_ERR — Raw Status of Interrupt from correctable error of corresponding CPUSet only if Interupt is unmasked in corresponding R5SS*_CPU*_ECC_UNCORR_ERRAGG_MASK registerWrie 0x1 to clear this interrupt.
  [2] R5SS1_CPU0_ECC_UNCORR_ERRAGG_STATUS_RAW_R5SS1_CPU0_B0TCM_UNCORR_ERR — Raw Status of Interrupt from correctable error of corresponding CPUSet only if Interupt is unmasked in corresponding R5SS*_CPU*_ECC_UNCORR_ERRAGG_MASK registerWrie 0x1 to clear this interrupt.
  [1] R5SS1_CPU0_ECC_UNCORR_ERRAGG_STATUS_RAW_R5SS1_CPU0_B1TCM_UNCORR_ERR — Raw Status of Interrupt from correctable error of corresponding CPUSet only if Interupt is unmasked in corresponding R5SS*_CPU*_ECC_UNCORR_ERRAGG_MASK registerWrie 0x1 to clear this interrupt.
  [0] R5SS1_CPU0_ECC_UNCORR_ERRAGG_STATUS_RAW_R5SS1_CPU0_ATCM_UNCORR_ERR — Raw Status of Interrupt from correctable error of corresponding CPUSet only if Interupt is unmasked in corresponding R5SS*_CPU*_ECC_UNCORR_ERRAGG_MASK registerWrie 0x1 to clear this interrupt.
0x180E0 MSS_CTRL_R5SS1_CORE1_ECC_CORR_ERRAGG_MASK
  [6] R5SS1_CPU1_ECC_CORR_ERRAGG_MASK_R5SS1_CPU1_IDATA_CORR_ERR — Mask Interrupt for correctable errors to aggregated Interrupt of corresponding CPU1'b1 : Interrupt is Masked1'b0 : Interrupt is Unmasked
  [5] R5SS1_CPU1_ECC_CORR_ERRAGG_MASK_R5SS1_CPU1_ITAG_CORR_ERR — Mask Interrupt for correctable errors to aggregated Interrupt of corresponding CPU1'b1 : Interrupt is Masked1'b0 : Interrupt is Unmasked
  [4] R5SS1_CPU1_ECC_CORR_ERRAGG_MASK_R5SS1_CPU1_DDATA_CORR_ERR — Mask Interrupt for correctable errors to aggregated Interrupt of corresponding CPU1'b1 : Interrupt is Masked1'b0 : Interrupt is Unmasked
  [3] R5SS1_CPU1_ECC_CORR_ERRAGG_MASK_R5SS1_CPU1_DTAG_CORR_ERR — Mask Interrupt for correctable errors to aggregated Interrupt of corresponding CPU1'b1 : Interrupt is Masked1'b0 : Interrupt is Unmasked
  [2] R5SS1_CPU1_ECC_CORR_ERRAGG_MASK_R5SS1_CPU1_B0TCM_CORR_ERR — Mask Interrupt for correctable errors to aggregated Interrupt of corresponding CPU1'b1 : Interrupt is Masked1'b0 : Interrupt is Unmasked
  [1] R5SS1_CPU1_ECC_CORR_ERRAGG_MASK_R5SS1_CPU1_B1TCM_CORR_ERR — Mask Interrupt for correctable errors to aggregated Interrupt of corresponding CPU1'b1 : Interrupt is Masked1'b0 : Interrupt is Unmasked
  [0] R5SS1_CPU1_ECC_CORR_ERRAGG_MASK_R5SS1_CPU1_ATCM_CORR_ERR — Mask Interrupt for correctable errors to aggregated Interrupt of corresponding CPU1'b1 : Interrupt is Masked1'b0 : Interrupt is Unmasked
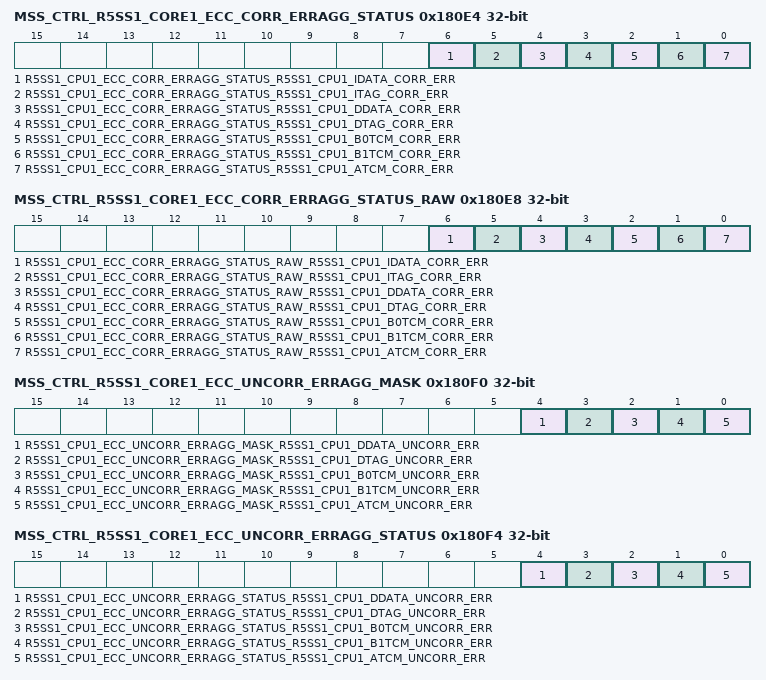
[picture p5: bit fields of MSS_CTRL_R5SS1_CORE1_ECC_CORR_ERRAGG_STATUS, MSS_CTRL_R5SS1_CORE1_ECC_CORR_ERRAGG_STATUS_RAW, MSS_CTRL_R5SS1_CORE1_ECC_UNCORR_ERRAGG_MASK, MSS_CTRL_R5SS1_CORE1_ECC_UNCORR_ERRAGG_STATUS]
0x180E4 MSS_CTRL_R5SS1_CORE1_ECC_CORR_ERRAGG_STATUS
  [6] R5SS1_CPU1_ECC_CORR_ERRAGG_STATUS_R5SS1_CPU1_IDATA_CORR_ERR — Status of Interrupt from correctable error of corresponding CPUSet only if Interupt is unmasked in corresponding R5SS*_CPU*_ECC_CORR_ERRAGG_MASK registerWrie 0x1 to clear this interrupt.
  [5] R5SS1_CPU1_ECC_CORR_ERRAGG_STATUS_R5SS1_CPU1_ITAG_CORR_ERR — Status of Interrupt from correctable error of corresponding CPUSet only if Interupt is unmasked in corresponding R5SS*_CPU*_ECC_CORR_ERRAGG_MASK registerWrie 0x1 to clear this interrupt.
  [4] R5SS1_CPU1_ECC_CORR_ERRAGG_STATUS_R5SS1_CPU1_DDATA_CORR_ERR — Status of Interrupt from correctable error of corresponding CPUSet only if Interupt is unmasked in corresponding R5SS*_CPU*_ECC_CORR_ERRAGG_MASK registerWrie 0x1 to clear this interrupt.
  [3] R5SS1_CPU1_ECC_CORR_ERRAGG_STATUS_R5SS1_CPU1_DTAG_CORR_ERR — Status of Interrupt from correctable error of corresponding CPUSet only if Interupt is unmasked in corresponding R5SS*_CPU*_ECC_CORR_ERRAGG_MASK registerWrie 0x1 to clear this interrupt.
  [2] R5SS1_CPU1_ECC_CORR_ERRAGG_STATUS_R5SS1_CPU1_B0TCM_CORR_ERR — Status of Interrupt from correctable error of corresponding CPUSet only if Interupt is unmasked in corresponding R5SS*_CPU*_ECC_CORR_ERRAGG_MASK registerWrie 0x1 to clear this interrupt.
  [1] R5SS1_CPU1_ECC_CORR_ERRAGG_STATUS_R5SS1_CPU1_B1TCM_CORR_ERR — Status of Interrupt from correctable error of corresponding CPUSet only if Interupt is unmasked in corresponding R5SS*_CPU*_ECC_CORR_ERRAGG_MASK registerWrie 0x1 to clear this interrupt.
  [0] R5SS1_CPU1_ECC_CORR_ERRAGG_STATUS_R5SS1_CPU1_ATCM_CORR_ERR — Status of Interrupt from correctable error of corresponding CPUSet only if Interupt is unmasked in corresponding R5SS*_CPU*_ECC_CORR_ERRAGG_MASK registerWrie 0x1 to clear this interrupt.
0x180E8 MSS_CTRL_R5SS1_CORE1_ECC_CORR_ERRAGG_STATUS_RAW
  [6] R5SS1_CPU1_ECC_CORR_ERRAGG_STATUS_RAW_R5SS1_CPU1_IDATA_CORR_ERR — Raw Status of Interrupt from correctable error of corresponding CPUSet only if Interupt is unmasked in corresponding R5SS*_CPU*_ECC_CORR_ERRAGG_MASK registerWrie 0x1 to clear this interrupt.
  [5] R5SS1_CPU1_ECC_CORR_ERRAGG_STATUS_RAW_R5SS1_CPU1_ITAG_CORR_ERR — Raw Status of Interrupt from correctable error of corresponding CPUSet only if Interupt is unmasked in corresponding R5SS*_CPU*_ECC_CORR_ERRAGG_MASK registerWrie 0x1 to clear this interrupt.
  [4] R5SS1_CPU1_ECC_CORR_ERRAGG_STATUS_RAW_R5SS1_CPU1_DDATA_CORR_ERR — Raw Status of Interrupt from correctable error of corresponding CPUSet only if Interupt is unmasked in corresponding R5SS*_CPU*_ECC_CORR_ERRAGG_MASK registerWrie 0x1 to clear this interrupt.
  [3] R5SS1_CPU1_ECC_CORR_ERRAGG_STATUS_RAW_R5SS1_CPU1_DTAG_CORR_ERR — Raw Status of Interrupt from correctable error of corresponding CPUSet only if Interupt is unmasked in corresponding R5SS*_CPU*_ECC_CORR_ERRAGG_MASK registerWrie 0x1 to clear this interrupt.
  [2] R5SS1_CPU1_ECC_CORR_ERRAGG_STATUS_RAW_R5SS1_CPU1_B0TCM_CORR_ERR — Raw Status of Interrupt from correctable error of corresponding CPUSet only if Interupt is unmasked in corresponding R5SS*_CPU*_ECC_CORR_ERRAGG_MASK registerWrie 0x1 to clear this interrupt.
  [1] R5SS1_CPU1_ECC_CORR_ERRAGG_STATUS_RAW_R5SS1_CPU1_B1TCM_CORR_ERR — Raw Status of Interrupt from correctable error of corresponding CPUSet only if Interupt is unmasked in corresponding R5SS*_CPU*_ECC_CORR_ERRAGG_MASK registerWrie 0x1 to clear this interrupt.
  [0] R5SS1_CPU1_ECC_CORR_ERRAGG_STATUS_RAW_R5SS1_CPU1_ATCM_CORR_ERR — Raw Status of Interrupt from correctable error of corresponding CPUSet only if Interupt is unmasked in corresponding R5SS*_CPU*_ECC_CORR_ERRAGG_MASK registerWrie 0x1 to clear this interrupt.
0x180F0 MSS_CTRL_R5SS1_CORE1_ECC_UNCORR_ERRAGG_MASK
  [4] R5SS1_CPU1_ECC_UNCORR_ERRAGG_MASK_R5SS1_CPU1_DDATA_UNCORR_ERR — Mask Interrupt for correctable errors to aggregated Interrupt of corresponding CPU1'b1 : Interrupt is Masked1'b0 : Interrupt is Unmasked
  [3] R5SS1_CPU1_ECC_UNCORR_ERRAGG_MASK_R5SS1_CPU1_DTAG_UNCORR_ERR — Mask Interrupt for correctable errors to aggregated Interrupt of corresponding CPU1'b1 : Interrupt is Masked1'b0 : Interrupt is Unmasked
  [2] R5SS1_CPU1_ECC_UNCORR_ERRAGG_MASK_R5SS1_CPU1_B0TCM_UNCORR_ERR — Mask Interrupt for correctable errors to aggregated Interrupt of corresponding CPU1'b1 : Interrupt is Masked1'b0 : Interrupt is Unmasked
  [1] R5SS1_CPU1_ECC_UNCORR_ERRAGG_MASK_R5SS1_CPU1_B1TCM_UNCORR_ERR — Mask Interrupt for correctable errors to aggregated Interrupt of corresponding CPU1'b1 : Interrupt is Masked1'b0 : Interrupt is Unmasked
  [0] R5SS1_CPU1_ECC_UNCORR_ERRAGG_MASK_R5SS1_CPU1_ATCM_UNCORR_ERR — Mask Interrupt for correctable errors to aggregated Interrupt of corresponding CPU1'b1 : Interrupt is Masked1'b0 : Interrupt is Unmasked
0x180F4 MSS_CTRL_R5SS1_CORE1_ECC_UNCORR_ERRAGG_STATUS
  [4] R5SS1_CPU1_ECC_UNCORR_ERRAGG_STATUS_R5SS1_CPU1_DDATA_UNCORR_ERR — Status of Interrupt from correctable error of corresponding CPUSet only if Interupt is unmasked in corresponding R5SS*_CPU*_ECC_UNCORR_ERRAGG_MASK registerWrie 0x1 to clear this interrupt.
  [3] R5SS1_CPU1_ECC_UNCORR_ERRAGG_STATUS_R5SS1_CPU1_DTAG_UNCORR_ERR — Status of Interrupt from correctable error of corresponding CPUSet only if Interupt is unmasked in corresponding R5SS*_CPU*_ECC_UNCORR_ERRAGG_MASK registerWrie 0x1 to clear this interrupt.
  [2] R5SS1_CPU1_ECC_UNCORR_ERRAGG_STATUS_R5SS1_CPU1_B0TCM_UNCORR_ERR — Status of Interrupt from correctable error of corresponding CPUSet only if Interupt is unmasked in corresponding R5SS*_CPU*_ECC_UNCORR_ERRAGG_MASK registerWrie 0x1 to clear this interrupt.
  [1] R5SS1_CPU1_ECC_UNCORR_ERRAGG_STATUS_R5SS1_CPU1_B1TCM_UNCORR_ERR — Status of Interrupt from correctable error of corresponding CPUSet only if Interupt is unmasked in corresponding R5SS*_CPU*_ECC_UNCORR_ERRAGG_MASK registerWrie 0x1 to clear this interrupt.
  [0] R5SS1_CPU1_ECC_UNCORR_ERRAGG_STATUS_R5SS1_CPU1_ATCM_UNCORR_ERR — Status of Interrupt from correctable error of corresponding CPUSet only if Interupt is unmasked in corresponding R5SS*_CPU*_ECC_UNCORR_ERRAGG_MASK registerWrie 0x1 to clear this interrupt.
